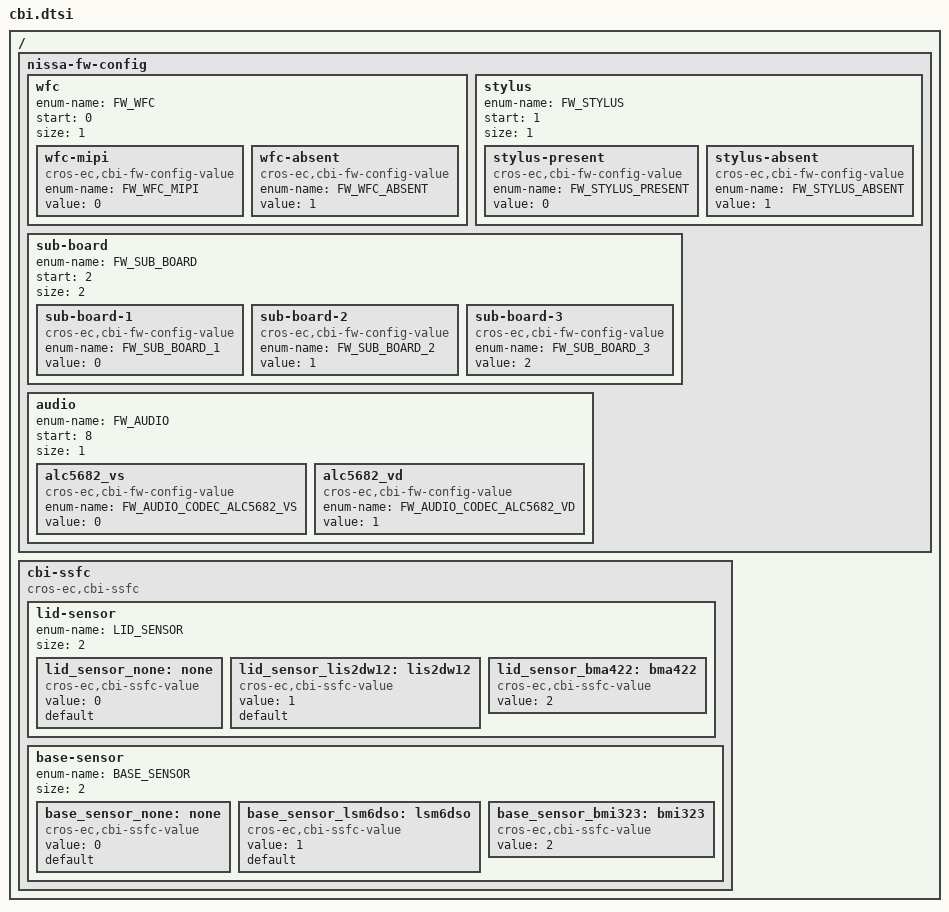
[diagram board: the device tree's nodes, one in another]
/* Copyright 2022 The ChromiumOS Authors
 * Use of this source code is governed by a BSD-style license that can be
 * found in the LICENSE file.
 */

/ {
	/* Xivu-specific fw_config fields. */
	nissa-fw-config {
		/*
		 * FW_CONFIG field to enable WFC or not.
		 */
		 wfc {
			enum-name = "FW_WFC";
			start = <0>;
			size = <1>;

			wfc-mipi {
				compatible = "cros-ec,cbi-fw-config-value";
				enum-name = "FW_WFC_MIPI";
				value = <0>;
			};
			wfc-absent {
				compatible = "cros-ec,cbi-fw-config-value";
				enum-name = "FW_WFC_ABSENT";
				value = <1>;
			};
		 };

		/*
		 * FW_CONFIG field to enable stylus or not.
		 */
		 stylus {
			enum-name = "FW_STYLUS";
			start = <1>;
			size = <1>;

			stylus-present {
				compatible = "cros-ec,cbi-fw-config-value";
				enum-name = "FW_STYLUS_PRESENT";
				value = <0>;
			};
			stylus-absent {
				compatible = "cros-ec,cbi-fw-config-value";
				enum-name = "FW_STYLUS_ABSENT";
				value = <1>;
			};
		 };
		/*
		 * FW_CONFIG field to indicate which sub-board
		 * is attached.
		 */
		sub-board {
			enum-name = "FW_SUB_BOARD";
			start = <2>;
			size = <2>;

			sub-board-1 {
				compatible = "cros-ec,cbi-fw-config-value";
				enum-name = "FW_SUB_BOARD_1";
				value = <0>;
			};
			sub-board-2 {
				compatible = "cros-ec,cbi-fw-config-value";
				enum-name = "FW_SUB_BOARD_2";
				value = <1>;
			};
			sub-board-3 {
				compatible = "cros-ec,cbi-fw-config-value";
				enum-name = "FW_SUB_BOARD_3";
				value = <2>;
			};
		};

		/*
		 * FW_CONFIG field to defined for AUDIO CODEC.
		 */
		audio {
			enum-name = "FW_AUDIO";
			start = <8>;
			size = <1>;

			alc5682_vs {
				compatible = "cros-ec,cbi-fw-config-value";
				enum-name = "FW_AUDIO_CODEC_ALC5682_VS";
				value = <0>;
			};
			alc5682_vd {
				compatible = "cros-ec,cbi-fw-config-value";
				enum-name = "FW_AUDIO_CODEC_ALC5682_VD";
				value = <1>;
			};
		};

/delete-node/ fan;
	};

	/* Xivu-specific ssfc fields. */
	cbi-ssfc {
		compatible = "cros-ec,cbi-ssfc";
		/*
		 * SSFC field to identify LID motion sensor.
		 */
		lid-sensor {
			enum-name = "LID_SENSOR";
			size = <2>;

			lid_sensor_none: none {
				compatible = "cros-ec,cbi-ssfc-value";
				status = "okay";
				value = <0>;
				default;
			};

			lid_sensor_lis2dw12: lis2dw12 {
				compatible = "cros-ec,cbi-ssfc-value";
				status = "okay";
				value = <1>;
				default;
			};
			lid_sensor_bma422: bma422 {
				compatible = "cros-ec,cbi-ssfc-value";
				status = "okay";
				value = <2>;
			};
		};
		/*
		 * SSFC field to identify BASE motion sensor.
		 */
		base-sensor {
			enum-name = "BASE_SENSOR";
			size = <2>;

			base_sensor_none: none {
				compatible = "cros-ec,cbi-ssfc-value";
				status = "okay";
				value = <0>;
				default;
			};
			base_sensor_lsm6dso: lsm6dso {
				compatible = "cros-ec,cbi-ssfc-value";
				status = "okay";
				value = <1>;
				default;
			};
			base_sensor_bmi323: bmi323 {
				compatible = "cros-ec,cbi-ssfc-value";
				status = "okay";
				value = <2>;
			};
		};
	};

};
